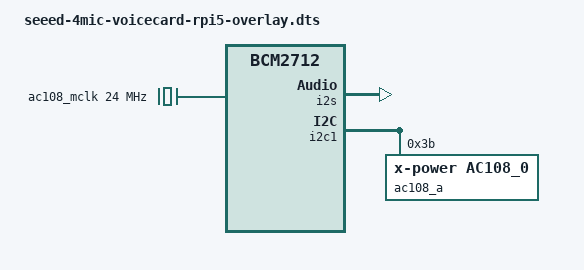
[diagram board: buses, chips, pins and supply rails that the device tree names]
/dts-v1/;
/plugin/;

/ {
	compatible = "brcm,bcm2708", "brcm,bcm2835", "brcm,bcm2836", "brcm,bcm2837", "brcm,bcm2711", "brcm,bcm2712";

	fragment@0 {
		target = <&i2s>;
		__overlay__ {
			status = "okay";
		};
	};

	fragment@1 {
		target-path = "/";
		__overlay__ {
			ac108_mclk: codec-mclk {
				compatible = "fixed-clock";
				#clock-cells = <0>;
				clock-frequency = <24000000>;
			};
		};
	};

	fragment@2 {
		target = <&i2c1>;
		__overlay__ {
			#address-cells = <1>;
			#size-cells = <0>;
			status = "okay";

			ac108_a: ac108@3b {
				compatible = "x-power,ac108_0";
				reg = <0x3b>;
				#sound-dai-cells = <0>;
				data-protocol = <0>;
			};
		};
	};

	fragment@3 {
		target-path = "/";
		__overlay__ {
			sound_card: sound {
				compatible = "seeed-voicecard";
				seeed-voice-card,name = "seeed-4mic-voicecard";
				seeed-voice-card,channels-playback-override = <4>;
				seeed-voice-card,channels-capture-override = <4>;
				status = "okay";

				seeed-voice-card,dai-link {
					format = "i2s";
					// RPi5 designware-i2s as I2S master
					bitclock-master = <&sound_cpu>;
					frame-master = <&sound_cpu>;

					sound_cpu: seeed-voice-card,cpu {
						sound-dai = <&i2s>;
					};

					seeed-voice-card,codec {
						sound-dai = <&ac108_a>;
						clocks = <&ac108_mclk>;
						clock-names = "mclk";
					};
				};
			};
		};
	};

	__overrides__ {
		card-name = <&sound_card>,"seeed-voice-card,name";
	};
};
